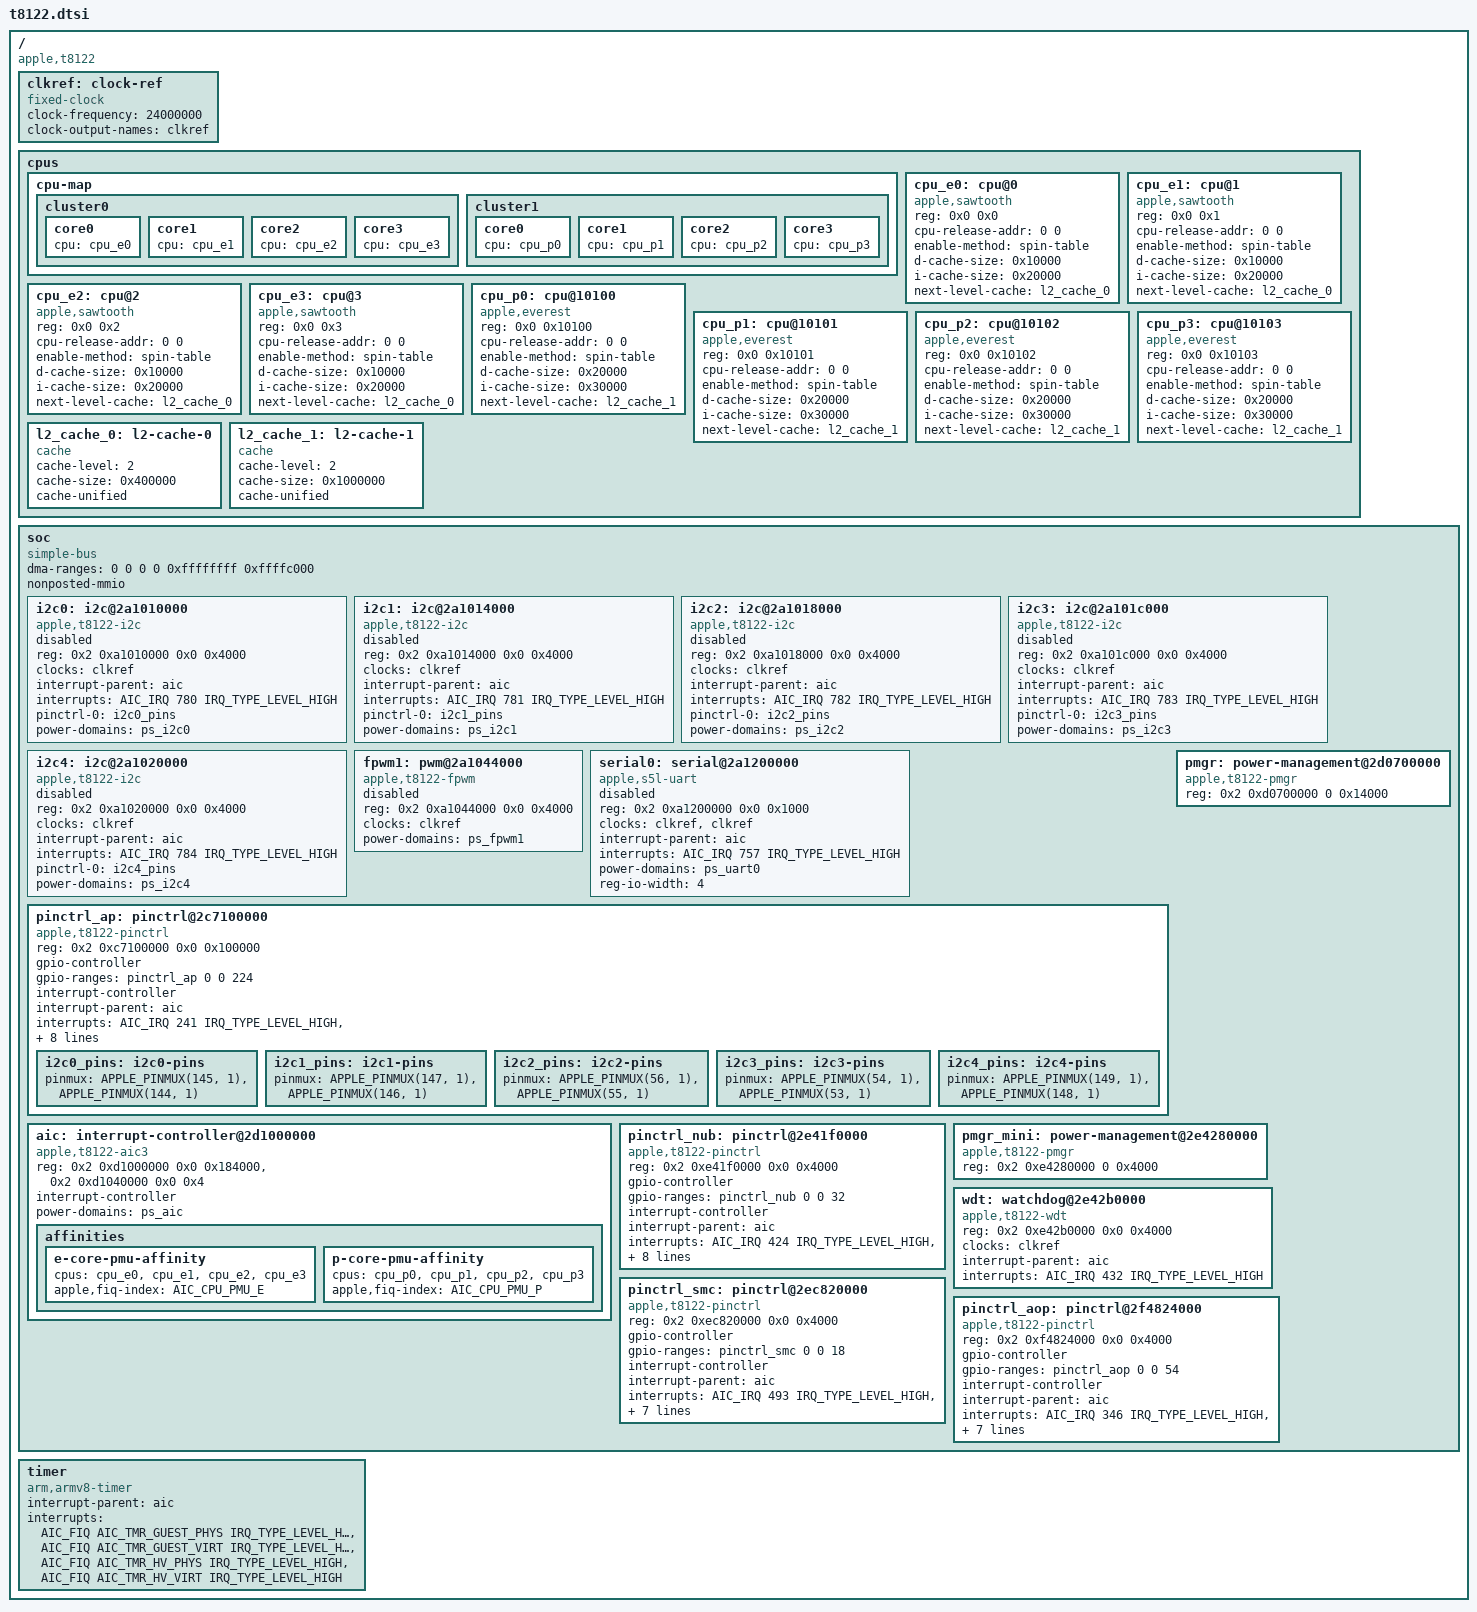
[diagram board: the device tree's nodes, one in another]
// SPDX-License-Identifier: GPL-2.0+ OR MIT
/*
 * Apple T8122 "M3" SoC
 *
 * Other names: H15G
 *
 * Copyright The Asahi Linux Contributors
 */

#include <dt-bindings/gpio/gpio.h>
#include <dt-bindings/interrupt-controller/apple-aic.h>
#include <dt-bindings/interrupt-controller/irq.h>
#include <dt-bindings/pinctrl/apple.h>
#include <dt-bindings/phy/phy.h>
#include <dt-bindings/spmi/spmi.h>

/ {
	compatible = "apple,t8122", "apple,arm-platform";

	#address-cells = <2>;
	#size-cells = <2>;

	clkref: clock-ref {
		compatible = "fixed-clock";
		#clock-cells = <0>;
		clock-frequency = <24000000>;
		clock-output-names = "clkref";
	};

	cpus {
		#address-cells = <2>;
		#size-cells = <0>;

		cpu-map {
			cluster0 {
				core0 {
					cpu = <&cpu_e0>;
				};

				core1 {
					cpu = <&cpu_e1>;
				};

				core2 {
					cpu = <&cpu_e2>;
				};

				core3 {
					cpu = <&cpu_e3>;
				};
			};

			cluster1 {
				core0 {
					cpu = <&cpu_p0>;
				};

				core1 {
					cpu = <&cpu_p1>;
				};

				core2 {
					cpu = <&cpu_p2>;
				};

				core3 {
					cpu = <&cpu_p3>;
				};
			};
		};

		cpu_e0: cpu@0 {
			device_type = "cpu";
			compatible = "apple,sawtooth";
			reg = <0x0 0x0>;
			cpu-release-addr = <0 0>; /* To be filled by loader */
			enable-method = "spin-table";

			d-cache-size = <0x10000>;
			i-cache-size = <0x20000>;
			next-level-cache = <&l2_cache_0>;
		};

		cpu_e1: cpu@1 {
			device_type = "cpu";
			compatible = "apple,sawtooth";
			reg = <0x0 0x1>;
			cpu-release-addr = <0 0>; /* To be filled by loader */
			enable-method = "spin-table";

			d-cache-size = <0x10000>;
			i-cache-size = <0x20000>;
			next-level-cache = <&l2_cache_0>;
		};

		cpu_e2: cpu@2 {
			device_type = "cpu";
			compatible = "apple,sawtooth";
			reg = <0x0 0x2>;
			cpu-release-addr = <0 0>; /* To be filled by loader */
			enable-method = "spin-table";

			d-cache-size = <0x10000>;
			i-cache-size = <0x20000>;
			next-level-cache = <&l2_cache_0>;
		};

		cpu_e3: cpu@3 {
			device_type = "cpu";
			compatible = "apple,sawtooth";
			reg = <0x0 0x3>;
			cpu-release-addr = <0 0>; /* To be filled by loader */
			enable-method = "spin-table";

			d-cache-size = <0x10000>;
			i-cache-size = <0x20000>;
			next-level-cache = <&l2_cache_0>;
		};

		cpu_p0: cpu@10100 {
			device_type = "cpu";
			compatible = "apple,everest";
			reg = <0x0 0x10100>;
			cpu-release-addr = <0 0>; /* To be filled by loader */
			enable-method = "spin-table";

			d-cache-size = <0x20000>;
			i-cache-size = <0x30000>;
			next-level-cache = <&l2_cache_1>;
		};

		cpu_p1: cpu@10101 {
			device_type = "cpu";
			compatible = "apple,everest";
			reg = <0x0 0x10101>;
			cpu-release-addr = <0 0>; /* To be filled by loader */
			enable-method = "spin-table";

			d-cache-size = <0x20000>;
			i-cache-size = <0x30000>;
			next-level-cache = <&l2_cache_1>;
		};

		cpu_p2: cpu@10102 {
			device_type = "cpu";
			compatible = "apple,everest";
			reg = <0x0 0x10102>;
			cpu-release-addr = <0 0>; /* To be filled by loader */
			enable-method = "spin-table";

			d-cache-size = <0x20000>;
			i-cache-size = <0x30000>;
			next-level-cache = <&l2_cache_1>;
		};

		cpu_p3: cpu@10103 {
			device_type = "cpu";
			compatible = "apple,everest";
			reg = <0x0 0x10103>;
			cpu-release-addr = <0 0>; /* To be filled by loader */
			enable-method = "spin-table";

			d-cache-size = <0x20000>;
			i-cache-size = <0x30000>;
			next-level-cache = <&l2_cache_1>;
		};

		l2_cache_0: l2-cache-0 {
			compatible = "cache";
			cache-level = <2>;
			cache-size = <0x400000>;
			cache-unified;
		};

		l2_cache_1: l2-cache-1 {
			compatible = "cache";
			cache-level = <2>;
			cache-size = <0x1000000>;
			cache-unified;
		};
	};

	soc {
		compatible = "simple-bus";
		ranges;
		#address-cells = <2>;

		/* Required to get >32-bit DMA via DARTs */
		dma-ranges = <0 0 0 0 0xffffffff 0xffffc000>;
		nonposted-mmio;
		#size-cells = <2>;

		i2c0: i2c@2a1010000 {
			compatible = "apple,t8122-i2c", "apple,t8103-i2c";
			reg = <0x2 0xa1010000 0x0 0x4000>;
			#address-cells = <0x1>;
			clocks = <&clkref>;
			interrupt-parent = <&aic>;
			interrupts = <AIC_IRQ 780 IRQ_TYPE_LEVEL_HIGH>;
			pinctrl-0 = <&i2c0_pins>;
			pinctrl-names = "default";
			power-domains = <&ps_i2c0>;
			#size-cells = <0x0>;

			status = "disabled";
		};

		i2c1: i2c@2a1014000 {
			compatible = "apple,t8122-i2c", "apple,t8103-i2c";
			reg = <0x2 0xa1014000 0x0 0x4000>;
			#address-cells = <0x1>;
			clocks = <&clkref>;
			interrupt-parent = <&aic>;
			interrupts = <AIC_IRQ 781 IRQ_TYPE_LEVEL_HIGH>;
			pinctrl-0 = <&i2c1_pins>;
			pinctrl-names = "default";
			power-domains = <&ps_i2c1>;
			#size-cells = <0x0>;

			status = "disabled";
		};

		i2c2: i2c@2a1018000 {
			compatible = "apple,t8122-i2c", "apple,t8103-i2c";
			reg = <0x2 0xa1018000 0x0 0x4000>;
			#address-cells = <0x1>;
			clocks = <&clkref>;
			interrupt-parent = <&aic>;
			interrupts = <AIC_IRQ 782 IRQ_TYPE_LEVEL_HIGH>;
			pinctrl-0 = <&i2c2_pins>;
			pinctrl-names = "default";
			power-domains = <&ps_i2c2>;
			#size-cells = <0x0>;

			status = "disabled";
		};

		i2c3: i2c@2a101c000 {
			compatible = "apple,t8122-i2c", "apple,t8103-i2c";
			reg = <0x2 0xa101c000 0x0 0x4000>;
			#address-cells = <0x1>;
			clocks = <&clkref>;
			interrupt-parent = <&aic>;
			interrupts = <AIC_IRQ 783 IRQ_TYPE_LEVEL_HIGH>;
			pinctrl-0 = <&i2c3_pins>;
			pinctrl-names = "default";
			power-domains = <&ps_i2c3>;
			#size-cells = <0x0>;

			status = "disabled";
		};

		i2c4: i2c@2a1020000 {
			compatible = "apple,t8122-i2c", "apple,t8103-i2c";
			reg = <0x2 0xa1020000 0x0 0x4000>;
			#address-cells = <0x1>;
			clocks = <&clkref>;
			interrupt-parent = <&aic>;
			interrupts = <AIC_IRQ 784 IRQ_TYPE_LEVEL_HIGH>;
			pinctrl-0 = <&i2c4_pins>;
			pinctrl-names = "default";
			power-domains = <&ps_i2c4>;
			#size-cells = <0x0>;

			status = "disabled";
		};

		fpwm1: pwm@2a1044000 {
			compatible = "apple,t8122-fpwm", "apple,s5l-fpwm";
			reg = <0x2 0xa1044000 0x0 0x4000>;
			clocks = <&clkref>;
			power-domains = <&ps_fpwm1>;
			#pwm-cells = <2>;

			status = "disabled";
		};

		serial0: serial@2a1200000 {
			compatible = "apple,s5l-uart";
			reg = <0x2 0xa1200000 0x0 0x1000>;
			/*
			 * TODO: figure out the clocking properly, there may
			 * be a third selectable clock.
			 */
			clocks = <&clkref>, <&clkref>;
			clock-names = "uart", "clk_uart_baud0";
			interrupt-parent = <&aic>;
			interrupts = <AIC_IRQ 757 IRQ_TYPE_LEVEL_HIGH>;
			power-domains = <&ps_uart0>;
			reg-io-width = <4>;

			status = "disabled";
		};

		pinctrl_ap: pinctrl@2c7100000 {
			compatible = "apple,t8122-pinctrl", "apple,t8103-pinctrl";
			reg = <0x2 0xc7100000 0x0 0x100000>;

			#gpio-cells = <2>;
			gpio-controller;
			gpio-ranges = <&pinctrl_ap 0 0 224>;

			#interrupt-cells = <2>;
			interrupt-controller;
			interrupt-parent = <&aic>;
			interrupts = <AIC_IRQ 241 IRQ_TYPE_LEVEL_HIGH>,
				     <AIC_IRQ 242 IRQ_TYPE_LEVEL_HIGH>,
				     <AIC_IRQ 243 IRQ_TYPE_LEVEL_HIGH>,
				     <AIC_IRQ 244 IRQ_TYPE_LEVEL_HIGH>,
				     <AIC_IRQ 245 IRQ_TYPE_LEVEL_HIGH>,
				     <AIC_IRQ 246 IRQ_TYPE_LEVEL_HIGH>,
				     <AIC_IRQ 247 IRQ_TYPE_LEVEL_HIGH>;

			power-domains = <&ps_gpio>;
			apple,npins = <224>;

			i2c0_pins: i2c0-pins {
				pinmux = <APPLE_PINMUX(145, 1)>,
					 <APPLE_PINMUX(144, 1)>;
			};

			i2c1_pins: i2c1-pins {
				pinmux = <APPLE_PINMUX(147, 1)>,
					 <APPLE_PINMUX(146, 1)>;
			};

			i2c2_pins: i2c2-pins {
				pinmux = <APPLE_PINMUX(56, 1)>,
					 <APPLE_PINMUX(55, 1)>;
			};

			i2c3_pins: i2c3-pins {
				pinmux = <APPLE_PINMUX(54, 1)>,
					 <APPLE_PINMUX(53, 1)>;
			};

			i2c4_pins: i2c4-pins {
				pinmux = <APPLE_PINMUX(149, 1)>,
					 <APPLE_PINMUX(148, 1)>;
			};
		};

		pmgr: power-management@2d0700000 {
			compatible = "apple,t8122-pmgr", "apple,t8103-pmgr",
				     "syscon", "simple-mfd";
			reg = <0x2 0xd0700000 0 0x14000>;
			#address-cells = <1>;
			#size-cells = <1>;
			/* child nodes are added in t8122-pmgr.dtsi */
		};

		aic: interrupt-controller@2d1000000 {
			compatible = "apple,t8122-aic3";
			reg = <0x2 0xd1000000 0x0 0x184000>,
			      <0x2 0xd1040000 0x0 0x4>;
			reg-names = "core", "event";
			#interrupt-cells = <3>;
			interrupt-controller;
			power-domains = <&ps_aic>;

			affinities {
				e-core-pmu-affinity {
					cpus = <&cpu_e0 &cpu_e1 &cpu_e2 &cpu_e3>;
					apple,fiq-index = <AIC_CPU_PMU_E>;
				};

				p-core-pmu-affinity {
					cpus = <&cpu_p0 &cpu_p1 &cpu_p2 &cpu_p3>;
					apple,fiq-index = <AIC_CPU_PMU_P>;
				};
			};
		};

		pinctrl_nub: pinctrl@2e41f0000 {
			compatible = "apple,t8122-pinctrl", "apple,t8103-pinctrl";
			reg = <0x2 0xe41f0000 0x0 0x4000>;

			#gpio-cells = <2>;
			gpio-controller;
			gpio-ranges = <&pinctrl_nub 0 0 32>;

			#interrupt-cells = <2>;
			interrupt-controller;
			interrupt-parent = <&aic>;
			interrupts = <AIC_IRQ 424 IRQ_TYPE_LEVEL_HIGH>,
				     <AIC_IRQ 425 IRQ_TYPE_LEVEL_HIGH>,
				     <AIC_IRQ 426 IRQ_TYPE_LEVEL_HIGH>,
				     <AIC_IRQ 427 IRQ_TYPE_LEVEL_HIGH>,
				     <AIC_IRQ 428 IRQ_TYPE_LEVEL_HIGH>,
				     <AIC_IRQ 429 IRQ_TYPE_LEVEL_HIGH>,
				     <AIC_IRQ 430 IRQ_TYPE_LEVEL_HIGH>;

			power-domains = <&ps_nub_gpio>;
			apple,npins = <32>;
		};

		pmgr_mini: power-management@2e4280000 {
			compatible = "apple,t8122-pmgr", "apple,t8103-pmgr",
				     "syscon", "simple-mfd";
			reg = <0x2 0xe4280000 0 0x4000>;
			#address-cells = <1>;
			#size-cells = <1>;
			/* child nodes are added in t8122-pmgr.dtsi */
		};

		wdt: watchdog@2e42b0000 {
			compatible = "apple,t8122-wdt", "apple,t8103-wdt";
			reg = <0x2 0xe42b0000 0x0 0x4000>;
			clocks = <&clkref>;
			interrupt-parent = <&aic>;
			interrupts = <AIC_IRQ 432 IRQ_TYPE_LEVEL_HIGH>;
		};

		pinctrl_smc: pinctrl@2ec820000 {
			compatible = "apple,t8122-pinctrl", "apple,t8103-pinctrl";
			reg = <0x2 0xec820000 0x0 0x4000>;

			#gpio-cells = <2>;
			gpio-controller;
			gpio-ranges = <&pinctrl_smc 0 0 18>;

			#interrupt-cells = <2>;
			interrupt-controller;
			interrupt-parent = <&aic>;
			interrupts = <AIC_IRQ 493 IRQ_TYPE_LEVEL_HIGH>,
				     <AIC_IRQ 494 IRQ_TYPE_LEVEL_HIGH>,
				     <AIC_IRQ 495 IRQ_TYPE_LEVEL_HIGH>,
				     <AIC_IRQ 496 IRQ_TYPE_LEVEL_HIGH>,
				     <AIC_IRQ 497 IRQ_TYPE_LEVEL_HIGH>,
				     <AIC_IRQ 498 IRQ_TYPE_LEVEL_HIGH>,
				     <AIC_IRQ 499 IRQ_TYPE_LEVEL_HIGH>;

			apple,npins = <18>;
		};

		pinctrl_aop: pinctrl@2f4824000 {
			compatible = "apple,t8122-pinctrl", "apple,t8103-pinctrl";
			reg = <0x2 0xf4824000 0x0 0x4000>;

			#gpio-cells = <2>;
			gpio-controller;
			gpio-ranges = <&pinctrl_aop 0 0 54>;

			#interrupt-cells = <2>;
			interrupt-controller;
			interrupt-parent = <&aic>;
			interrupts = <AIC_IRQ 346 IRQ_TYPE_LEVEL_HIGH>,
				     <AIC_IRQ 347 IRQ_TYPE_LEVEL_HIGH>,
				     <AIC_IRQ 348 IRQ_TYPE_LEVEL_HIGH>,
				     <AIC_IRQ 349 IRQ_TYPE_LEVEL_HIGH>,
				     <AIC_IRQ 350 IRQ_TYPE_LEVEL_HIGH>,
				     <AIC_IRQ 351 IRQ_TYPE_LEVEL_HIGH>,
				     <AIC_IRQ 352 IRQ_TYPE_LEVEL_HIGH>;

			apple,npins = <54>;
		};
	};

	timer {
		compatible = "arm,armv8-timer";
		interrupt-parent = <&aic>;
		interrupts = <AIC_FIQ AIC_TMR_GUEST_PHYS IRQ_TYPE_LEVEL_HIGH>,
			     <AIC_FIQ AIC_TMR_GUEST_VIRT IRQ_TYPE_LEVEL_HIGH>,
			     <AIC_FIQ AIC_TMR_HV_PHYS IRQ_TYPE_LEVEL_HIGH>,
			     <AIC_FIQ AIC_TMR_HV_VIRT IRQ_TYPE_LEVEL_HIGH>;
		interrupt-names = "phys", "virt", "hyp-phys", "hyp-virt";
	};
};

#include "t8122-pmgr.dtsi"
